# USB0_RAMS_INJ_CFG register map
Vendor: Texas Instruments
Peripheral module from a debugger description file (folder J721S2).
Registers are 32-bit, read-only, reset values left out (the file's numbers can be read two ways) unless marked. A register's access mark holds for its fields unless they carry their own. Offsets are as the file gives them; lines under a group give offsets from that group; [hi:lo] are bit positions; {n}, {i} and the like mark numbered series; 'fields as' and 'values as' point back to an identical list; <NAME> marks a mode.

## USB0_RAMS_INJ_CFG
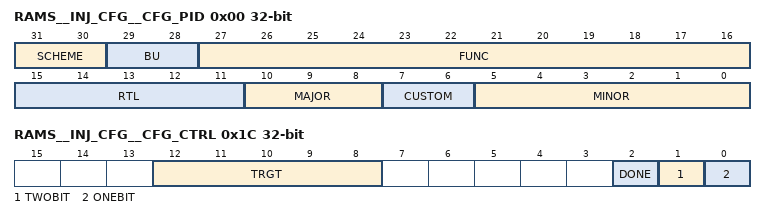
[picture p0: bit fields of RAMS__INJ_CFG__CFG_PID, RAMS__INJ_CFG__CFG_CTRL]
0x00 RAMS__INJ_CFG__CFG_PID — The Revision Register contains the major and minor revisions for the module.
  [31:30] SCHEME — PID register scheme
  [29:28] BU — Business Unit: 10 = Processors
  [27:16] FUNC — Module ID
  [15:11] RTL — RTL revision. Will vary depending on release.
  [10:8] MAJOR — Major revision
  [7:6] CUSTOM
  [5:0] MINOR — Minor revision
0x04 RAMS__INJ_CFG__CFG_INFO — The Info Register gives the configuration Inforrmation of this module.
  [5:0] ENDPOINTS — Total number of Targets supported by this configuration
0x08 RAMS__INJ_CFG__CFG_SFT_RST wo — The Global Soft Reset Register clears all programmable registers and returns the injector to idle state
  [3:0] KEY — Write 4'b1010 to issue a soft reset. All other written values are ignored. Always read as 0
0x10 RAMS__INJ_CFG__CFG_BIT1 rw — This register defines the first bit to be flipped when injection is enabled
  [15:0] BIT1 — First bit to be flipped on an error injection
0x14 RAMS__INJ_CFG__CFG_BIT2 rw — This register defines the second bit to be flipped if 2-bit injection is enabled
  [15:0] BIT2 — Second bit to be flipped on an error injection if 2-bit injection is chosen.
0x18 RAMS__INJ_CFG__CFG_TRGT rw — This is the target selection regsiter
  [4:0] TRGT — Select which target to interact with. Writes of a value higher than the number of targets supported by this configuration will have no effect
0x1C RAMS__INJ_CFG__CFG_CTRL access per field — Controls the injection
  [12:8] TRGT ro — Indicates which target is selected by the TRGT register
  [2] DONE ro — Indicates that the target selected by TRGT has completed error injection. This status supercedes the armed bit
  [1] TWOBIT rw — Write 1 to trigger a 2-bit error in target selected by TRGT regsiter. Write 0 to finish or cancel 2-bit injection. If both 1 and 2-bit injection are set, 2-bit injection will be performed
  [0] ONEBIT rw — Write 1 to trigger a 1-bit error in target selected by TRGT regsiter. Write 0 to finish or cancel 1-bit injection
0x20 RAMS__INJ_CFG__CFG_STATUS — Controls the injection
  [2] ARMED — Indicates that the target selected by TRGT is ARMED for error injection
